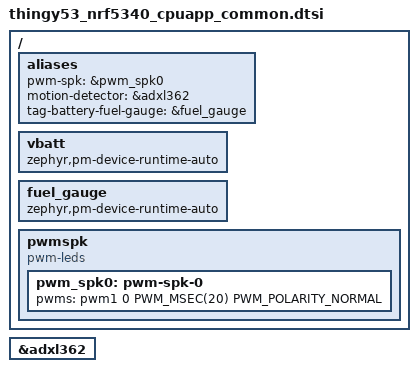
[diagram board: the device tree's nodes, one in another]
/*
 * Copyright (c) 2024-2026 Nordic Semiconductor ASA
 *
 * SPDX-License-Identifier: LicenseRef-Nordic-5-Clause
 */

/ {
	aliases {
		pwm-spk = &pwm_spk0;
		motion-detector = &adxl362;
		tag-battery-fuel-gauge = &fuel_gauge;
	};

	vbatt {
		status = "okay";
		zephyr,pm-device-runtime-auto;
	};

	fuel_gauge {
		status = "okay";
		zephyr,pm-device-runtime-auto;
	};

	pwmspk {
		compatible = "pwm-leds";

		pwm_spk0: pwm-spk-0 {
			pwms = <&pwm1 0 PWM_MSEC(20) PWM_POLARITY_NORMAL>;
		};
	};
};

&adxl362 {
	status = "okay";
};
